# TEST register map
File version: 0.2
TEST_BITS
CPU: CM0 r0p0, little endian, no MPU, no FPU, 2 interrupt priority bits
Registers are 32-bit, read-write, reset 0x0 unless marked. A register's access mark holds for its fields unless they carry their own. Offsets are from the block's base; lines under a group give offsets from that group; [hi:lo] are bit positions; {n}, {i} and the like mark numbered series; 'fields as' and 'values as' point back to an identical list; <NAME> marks a mode.

## Memory map
0x40064000 USART0 size 0xFFF — USART
0x40068000 USART1 size 0xFFF
0x4006C000 USART2 size 0xFFF

## Interrupts
3 UART0 (USART0)
4 UART1 (USART1)
5 UART2 (USART2)

## USART0 — USART
Base 0x40064000
Same registers: USART1 0x40068000, USART2 0x4006C000
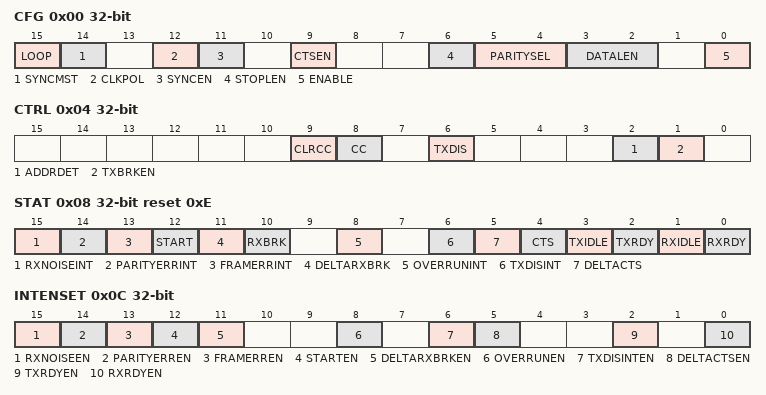
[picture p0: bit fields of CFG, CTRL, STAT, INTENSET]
0x00 CFG — USART Configuration register. Basic USART configuration settings that typically are not changed during operation.
  [15] LOOP — Selects data loopback mode.
    0=NORMAL_OPERATION_; 1=LOOPBACK_MODE_THIS_ (Loopback mode. This provides a mechanism to perform diagnostic loopback testing for USART data. Serial data from the transmitter (Un_TXD) is connected internally to serial input of the receive (Un_RXD). Un_TXD and Un_RTS activity will also appear on external pins if these functions are configured to appear on device pins. The receiver RTS signal is also looped back to CTS and performs flow control if enabled by CTSEN.)
  [14] SYNCMST — Synchronous mode Master select.
    0=SLAVE_WHEN_SYNCHRON (Slave. When synchronous mode is enabled, the USART is a slave.); 1=MASTER_WHEN_SYNCHRO (Master. When synchronous mode is enabled, the USART is a master. In asynchronous mode, the baud rate clock will be output on SCLK if it is connected to a pin.)
  [12] CLKPOL — Selects the clock polarity and sampling edge of received data in synchronous mode.
    0=FALLING_EDGE_UN_RXD (Falling edge. Un_RXD is sampled on the falling edge of SCLK.); 1=RISING_EDGE_UN_RXD_ (Rising edge. Un_RXD is sampled on the rising edge of SCLK.)
  [11] SYNCEN — Selects synchronous or asynchronous operation.
    0=ASYNCHRONOUS_MODE_IS (Asynchronous mode is selected.); 1=SYNCHRONOUS_MODE_IS_ (Synchronous mode is selected.)
  [9] CTSEN — CTS Enable. Determines whether CTS is used for flow control. CTS can be from the input pin, or from the USART's own RTS if loopback mode is enabled. See Section 16.7.3 for more information.
    0=NO_FLOW_CONTROL_THE (No flow control. The transmitter does not receive any automatic flow control signal.); 1=FLOW_CONTROL_ENABLED (Flow control enabled. The transmitter uses external or internal CTS for flow control purposes.)
  [6] STOPLEN — Number of stop bits appended to transmitted data. Only a single stop bit is required for received data.
    0=1_STOP_BIT_; 1=2_STOP_BITS_THIS_SE (2 stop bits. This setting should only be used for asynchronous communication.)
  [5:4] PARITYSEL — Selects what type of parity is used by the USART.
    0=NO_PARITY_; 2=EVEN_PARITY_ADDS_A_ (Even parity. Adds a bit to each character such that the number of 1s in a transmitted character is even, and the number of 1s in a received character is expected to be even.); 3=ODD_PARITY_ADDS_A_B (Odd parity. Adds a bit to each character such that the number of 1s in a transmitted character is odd, and the number of 1s in a received character is expected to be odd.)
  [3:2] DATALEN — Selects the data size for the USART.
    0=7_BIT_DATA_LENGTH_; 1=8_BIT_DATA_LENGTH_; 2=9_BIT_DATA_LENGTH_T (9 bit data length. The 9th bit is commonly used for addressing in multidrop mode. See the ADDRDET bit in the CTRL register.)
  [0] ENABLE — USART Enable.
    0=DISABLED_THE_USART_ (Disabled. The USART is disabled and the internal state machine and counters are reset. While Enable = 0, all USART interrupts are disabled. When Enable is set again, CFG and most other control bits remain unchanged. For instance, when re-enabled, the USART will immediately generate a TxRdy interrupt if enabled because the transmitter has been reset and is therefore available.); 1=ENABLED_THE_USART_I (Enabled. The USART is enabled for operation.)
0x04 CTRL — USART Control register. USART control settings that are more likely to change during operation.
  [9] CLRCC — Clear Continuous Clock.
    0=NO_AFFECT_ON_THE_CC_ (No affect on the CC bit.); 1=AUTO_CLEAR_THE_CC_B (Auto-clear. The CC bit is automatically cleared when a complete character has been received. This bit is cleared at the same time.)
  [8] CC — Continuous Clock generation. By default, SCLK is only output while data is being transmitted in synchronous mode.
    0=CLOCK_ON_CHARACTER_ (Clock on character. In synchronous mode, SCLK cycles only when characters are being sent on Un_TXD or to complete a character that is being received.); 1=CONTINUOUS_CLOCK_SC (Continuous clock. SCLK runs continuously in synchronous mode, allowing characters to be received on Un_RxD independently from transmission on Un_TXD).)
  [6] TXDIS — Transmit Disable.
    0=NOT_DISABLED_USART_ (Not disabled. USART transmitter is not disabled.); 1=DISABLED_USART_TRAN (Disabled. USART transmitter is disabled after any character currently being transmitted is complete. This feature can be used to facilitate software flow control.)
  [2] ADDRDET — Enable address detect mode.
    0=ENABLED_THE_USART_R (Enabled. The USART receiver is enabled for all incoming data.); 1=DISABLED_THE_USART_ (Disabled. The USART receiver ignores incoming data that does not have the most significant bit of the data (typically the 9th bit) = 1. When the data MSB bit = 1, the receiver treats the incoming data normally, generating a received data interrupt. Software can then check the data to see if this is an address that should be handled. If it is, the ADDRDET bit is cleared by software and further incoming data is handled normally.)
  [1] TXBRKEN — Break Enable.
    0=NORMAL_OPERATION_; 1=CONTINUOUS_BREAK_IS_ (Continuous break is sent immediately when this bit is set, and remains until this bit is cleared. A break may be sent without danger of corrupting any currently transmitting character if the transmitter is first disabled (TXDIS in CTRL is set) and then waiting for the transmitter to be disabled (TXDISINT in STAT = 1) before writing 1 to TXBRKEN.)
0x08 STAT reset 0xE — USART Status register. The complete status value can be read here. Writing 1s clears some bits in the register. Some bits can be cleared by writing a 1 to them.
  [15] RXNOISEINT — Received Noise interrupt flag. This bit is valid when there is a character to be read in the RXDATA register and reflects the status of that character. Three samples of received data are taken in order to determine the value of each received data bit, except in synchronous mode. This acts as a noise filter if one sample disagrees. The Noise bit is set when a received data bit contains one disagreeing sample. This could indicate line noise, a baud rate or character format mismatch, or loss of synchronization during data reception. RXNOISEINT is not updated during a received break.
  [14] PARITYERRINT — Parity Error interrupt flag. This flag is set when a parity error is detected in a received character, if parity is enabled via the Parity field in the CFG register.
  [13] FRAMERRINT — Framing Error interrupt flag. This flag is set when a character is received with a missing stop bit at the expected location. This could be an indication of a baud rate or configuration mismatch with the transmitting source.
  [12] START — This bit is set when a start is detected on the receiver input and subsequently confirmed by a mid-bit sample. Its purpose is primarily to allow wakeup from Power-down mode immediately when a start is detected. Cleared by software.
  [11] DELTARXBRK — This bit is set when a change in the state of receiver break detection occurs. Cleared by software.
  [10] RXBRK — Received Break. This bit reflects the current state of the receiver break detection logic. It is set when the Un_RXD pin remains low for 16 bit times. Note that FRAMERRINT will also be set when this condition occurs because the stop bit(s) for the character would be missing. RXBRK is cleared when the Un_RXD pin goes high.
  [8] OVERRUNINT — Overrun Error interrupt flag. This flag is set when a new character is received while the receiver buffer is still in use. If this occurs, the newly received character in the shift register is lost.
  [6] TXDISINT — Transmitter Disabled Interrupt flag. When 1, this bit indicates that the USART transmitter is fully idle after being disabled via the TXDIS in the CFG register (TXDIS = 1).
  [5] DELTACTS — This bit is set when a change in the state is detected for the CTS flag above. This bit is cleared by software.
  [4] CTS — This bit reflects the current state of the CTS signal, regardless of the setting of the CTSEN bit in the CFG register. This will be the value of the CTS input pin unless loopback mode is enabled.
  [3] TXIDLE — Transmitter Idle. When 0, indicates that the transmitter is currently in the process of sending data.When 1, indicate that the transmitter is not currently in the process of sending data.
  [2] TXRDY — Transmitter Ready flag. When 1, this bit indicates that data may be written to the transmit buffer. Previous data may still be in the process of being transmitted. Cleared when data is written to TXDATA until the data is moved to the transmit shift register.
  [1] RXIDLE — Receiver Idle. When 0, indicates that the receiver is currently in the process of receiving data. When 1, indicates that the receiver is not currently in the process of receiving data.
  [0] RXRDY — Receiver Ready flag. When 1, indicates that data is available to be read from the receiver buffer. Cleared after a read of the RXDATA or RXDATASTAT registers.
0x0C INTENSET — Interrupt Enable read and Set register. Contains an individual interrupt enable bit for each potential USART interrupt. A complete value may be read from this register. Writing a 1 to any implemented bit position causes that bit to be set.
  [15] RXNOISEEN — When 1, enables an interrupt when noise is detected. See description of the RXNOISEINT bit in Table 164.
  [14] PARITYERREN — When 1, enables an interrupt when a parity error has been detected.
  [13] FRAMERREN — When 1, enables an interrupt when a framing error has been detected.
  [12] STARTEN — When 1, enables an interrupt when a received start bit has been detected.
  [11] DELTARXBRKEN — When 1, enables an interrupt when a change of state has occurred in the detection of a received break condition (break condition asserted or deasserted).
  [8] OVERRUNEN — When 1, enables an interrupt when an overrun error occurred.
  [6] TXDISINTEN — When 1, enables an interrupt when the transmitter is fully disabled as indicated by the TXDISINT flag in STAT. See description of the TXDISINT bit for details.
  [5] DELTACTSEN — When 1, enables an interrupt when there is a change in the state of the CTS input.
  [2] TXRDYEN — When 1, enables an interrupt when the TXDATA register is available to take another character to transmit.
  [0] RXRDYEN — When 1, enables an interrupt when there is a received character available to be read from the RXDATA register.
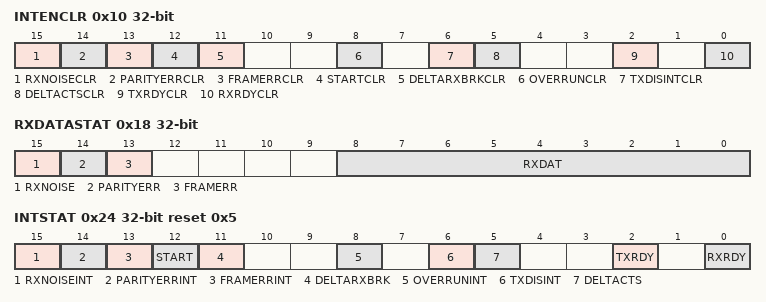
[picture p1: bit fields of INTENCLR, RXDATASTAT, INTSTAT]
0x10 INTENCLR wo reset not defined — Interrupt Enable Clear register. Allows clearing any combination of bits in the INTENSET register. Writing a 1 to any implemented bit position causes the corresponding bit to be cleared.
  [15] RXNOISECLR — Writing 1 clears the corresponding bit in the INTENSET register.
  [14] PARITYERRCLR — Writing 1 clears the corresponding bit in the INTENSET register.
  [13] FRAMERRCLR — Writing 1 clears the corresponding bit in the INTENSET register.
  [12] STARTCLR — Writing 1 clears the corresponding bit in the INTENSET register.
  [11] DELTARXBRKCLR — Writing 1 clears the corresponding bit in the INTENSET register.
  [8] OVERRUNCLR — Writing 1 clears the corresponding bit in the INTENSET register.
  [6] TXDISINTCLR — Writing 1 clears the corresponding bit in the INTENSET register.
  [5] DELTACTSCLR — Writing 1 clears the corresponding bit in the INTENSET register.
  [2] TXRDYCLR — Writing 1 clears the corresponding bit in the INTENSET register.
  [0] RXRDYCLR — Writing 1 clears the corresponding bit in the INTENSET register.
0x14 RXDATA ro reset not defined read-modifies — Receiver Data register. Contains the last character received.
  [8:0] RXDAT — The USART Receiver Data register contains the next received character. The number of bits that are relevant depends on the USART configuration settings.
0x18 RXDATASTAT ro reset not defined read-modifies — Receiver Data with Status register. Combines the last character received with the current USART receive status. Allows software to recover incoming data and status together.
  [15] RXNOISE — Received Noise flag. See description of the RxNoiseInt bit in Table 164.
  [14] PARITYERR — Parity Error status flag. This bit is valid when there is a character to be read in the RXDATA register and reflects the status of that character. This bit will be set when a parity error is detected in a received character.
  [13] FRAMERR — Framing Error status flag. This bit is valid when there is a character to be read in the RXDATA register and reflects the status of that character. This bit will set when the character in RXDAT was received with a missing stop bit at the expected location. This could be an indication of a baud rate or configuration mismatch with the transmitting source.
  [8:0] RXDAT — The USART Receiver Data register contains the next received character. The number of bits that are relevant depends on the USART configuration settings.
0x1C TXDATA — Transmit Data register. Data to be transmitted is written here.
  [8:0] TXDAT — Writing to the USART Transmit Data Register causes the data to be transmitted as soon as the transmit shift register is available.
0x20 BRG — Baud Rate Generator register. 16-bit integer baud rate divisor value.
  [15:0] BRGVAL — This value is used to divide the USART input clock to determine the baud rate, based on the input clock from the FRG. 0 = The FRG clock is used directly by the USART function. 1 = The FRG clock is divided by 2 before use by the USART function. 2 = The FRG clock is divided by 3 before use by the USART function. ... 0xFFFF = The FRG clock is divided by 65,536 before use by the USART function.
0x24 INTSTAT ro reset 0x5 — Interrupt status register. Reflects interrupts that are currently enabled.
  [15] RXNOISEINT — Received Noise interrupt flag.
  [14] PARITYERRINT — Parity Error interrupt flag.
  [13] FRAMERRINT — Framing Error interrupt flag.
  [12] START — This bit is set when a start is detected on the receiver input.
  [11] DELTARXBRK — This bit is set when a change in the state of receiver break detection occurs.
  [8] OVERRUNINT — Overrun Error interrupt flag.
  [6] TXDISINT — Transmitter Disabled Interrupt flag.
  [5] DELTACTS — This bit is set when a change in the state of the CTS input is detected.
  [2] TXRDY — Transmitter Ready flag.
  [0] RXRDY — Receiver Ready flag.
